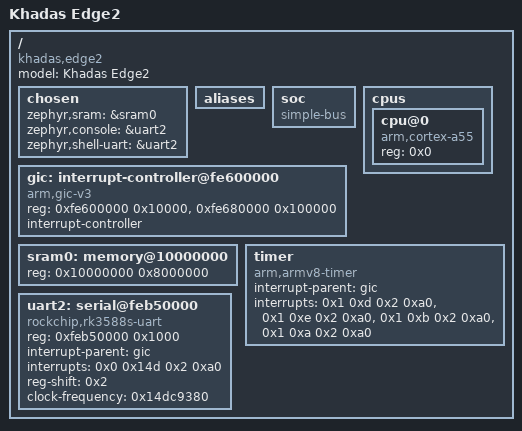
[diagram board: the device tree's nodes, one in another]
/dts-v1/;

/* node '/' defined in zephyr/dts/common/skeleton.dtsi:9 */
/ {
	#address-cells = < 0x1 >;    /* in zephyr/dts/arm64/rockchip/rk3588s.dtsi:11 */
	#size-cells = < 0x1 >;       /* in zephyr/dts/arm64/rockchip/rk3588s.dtsi:12 */
	model = "Khadas Edge2";      /* in zephyr/boards/khadas/edge2/khadas_edge2.dts:11 */
	compatible = "khadas,edge2"; /* in zephyr/boards/khadas/edge2/khadas_edge2.dts:12 */

	/* node '/chosen' defined in zephyr/dts/common/skeleton.dtsi:13 */
	chosen {
		zephyr,sram = &sram0;       /* in zephyr/boards/khadas/edge2/khadas_edge2.dts:15 */
		zephyr,console = &uart2;    /* in zephyr/boards/khadas/edge2/khadas_edge2.dts:16 */
		zephyr,shell-uart = &uart2; /* in zephyr/boards/khadas/edge2/khadas_edge2.dts:17 */
	};

	/* node '/aliases' defined in zephyr/dts/common/skeleton.dtsi:15 */
	aliases {
	};

	/* node '/soc' defined in zephyr/dts/arm64/armv8-a.dtsi:10 */
	soc {
		#address-cells = < 0x1 >;  /* in zephyr/dts/arm64/armv8-a.dtsi:11 */
		#size-cells = < 0x1 >;     /* in zephyr/dts/arm64/armv8-a.dtsi:12 */
		compatible = "simple-bus"; /* in zephyr/dts/arm64/armv8-a.dtsi:13 */
		ranges;                    /* in zephyr/dts/arm64/armv8-a.dtsi:14 */
	};

	/* node '/cpus' defined in zephyr/dts/arm64/rockchip/rk3588s.dtsi:14 */
	cpus {
		#address-cells = < 0x1 >; /* in zephyr/dts/arm64/rockchip/rk3588s.dtsi:15 */
		#size-cells = < 0x0 >;    /* in zephyr/dts/arm64/rockchip/rk3588s.dtsi:16 */

		/* node '/cpus/cpu@0' defined in zephyr/dts/arm64/rockchip/rk3588s.dtsi:18 */
		cpu@0 {
			device_type = "cpu";           /* in zephyr/dts/arm64/rockchip/rk3588s.dtsi:19 */
			compatible = "arm,cortex-a55"; /* in zephyr/dts/arm64/rockchip/rk3588s.dtsi:20 */
			reg = < 0x0 >;                 /* in zephyr/dts/arm64/rockchip/rk3588s.dtsi:21 */
		};
	};

	/* node '/interrupt-controller@fe600000' defined in zephyr/dts/arm64/rockchip/rk3588s.dtsi:67 */
	gic: interrupt-controller@fe600000 {
		#address-cells = < 0x1 >;      /* in zephyr/dts/arm64/rockchip/rk3588s.dtsi:68 */
		compatible = "arm,gic-v3",
		             "arm,gic";        /* in zephyr/dts/arm64/rockchip/rk3588s.dtsi:69 */
		reg = < 0xfe600000 0x10000 >,
		      < 0xfe680000 0x100000 >; /* in zephyr/dts/arm64/rockchip/rk3588s.dtsi:70 */
		interrupt-controller;          /* in zephyr/dts/arm64/rockchip/rk3588s.dtsi:72 */
		#interrupt-cells = < 0x4 >;    /* in zephyr/dts/arm64/rockchip/rk3588s.dtsi:73 */
		status = "okay";               /* in zephyr/dts/arm64/rockchip/rk3588s.dtsi:74 */
		phandle = < 0x1 >;             /* in zephyr/dts/arm64/rockchip/rk3588s.dtsi:83 */
	};

	/* node '/memory@10000000' defined in zephyr/dts/arm64/rockchip/rk3588s.dtsi:77 */
	sram0: memory@10000000 {
		reg = < 0x10000000 0x8000000 >; /* in zephyr/dts/arm64/rockchip/rk3588s.dtsi:78 */
	};

	/* node '/timer' defined in zephyr/dts/arm64/rockchip/rk3588s.dtsi:81 */
	timer {
		compatible = "arm,armv8-timer";    /* in zephyr/dts/arm64/rockchip/rk3588s.dtsi:82 */
		interrupt-parent = < &gic >;       /* in zephyr/dts/arm64/rockchip/rk3588s.dtsi:83 */
		interrupts = < 0x1 0xd 0x2 0xa0 >,
		             < 0x1 0xe 0x2 0xa0 >,
		             < 0x1 0xb 0x2 0xa0 >,
		             < 0x1 0xa 0x2 0xa0 >; /* in zephyr/dts/arm64/rockchip/rk3588s.dtsi:84 */
	};

	/* node '/serial@feb50000' defined in zephyr/dts/arm64/rockchip/rk3588s.dtsi:94 */
	uart2: serial@feb50000 {
		compatible = "rockchip,rk3588s-uart",
		             "ns16550";               /* in zephyr/dts/arm64/rockchip/rk3588s.dtsi:95 */
		reg = < 0xfeb50000 0x1000 >;          /* in zephyr/dts/arm64/rockchip/rk3588s.dtsi:96 */
		interrupt-parent = < &gic >;          /* in zephyr/dts/arm64/rockchip/rk3588s.dtsi:97 */
		interrupts = < 0x0 0x14d 0x2 0xa0 >;  /* in zephyr/dts/arm64/rockchip/rk3588s.dtsi:98 */
		reg-shift = < 0x2 >;                  /* in zephyr/dts/arm64/rockchip/rk3588s.dtsi:100 */
		clock-frequency = < 0x14dc9380 >;     /* in zephyr/dts/arm64/rockchip/rk3588s.dtsi:101 */
		status = "okay";                      /* in zephyr/boards/khadas/edge2/khadas_edge2.dts:32 */
	};
};
